# APM32M35XX register map
File version: 1.0
Registers are 32-bit, read-write, reset 0x0 unless marked. A register's access mark holds for its fields unless they carry their own. Offsets are from the block's base; [hi:lo] are bit positions; {n}, {i} and the like mark numbered series.

## SPI1 — Serial peripheral interface
Base 0x40013000
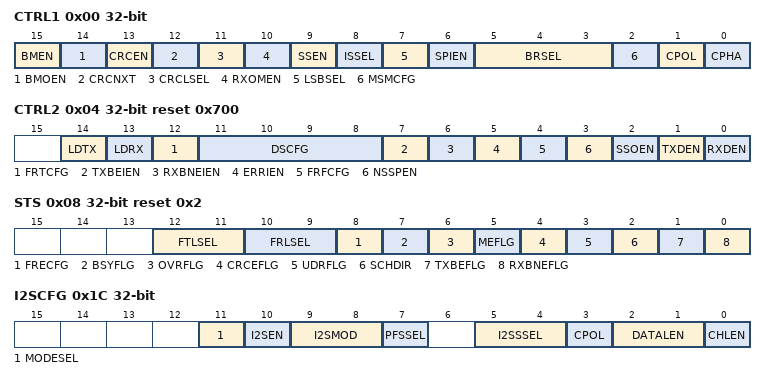
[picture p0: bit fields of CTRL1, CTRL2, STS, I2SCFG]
0x00 CTRL1 — control register 1
  [15] BMEN — Bidirectional data mode enable
  [14] BMOEN — Bidirectional Mode Output Enable
  [13] CRCEN — Hardware CRC calculation enable
  [12] CRCNXT — CRC transfer next
  [11] CRCLSEL — CRC Length Select
  [10] RXOMEN — Receive Only Mode Enable
  [9] SSEN — Software Slave Device Enable
  [8] ISSEL — Internal Slave Device Select
  [7] LSBSEL — LSB First Transfer Select
  [6] SPIEN — SPI enable
  [5:3] BRSEL — Baud Rate Divider Factor Selectl
  [2] MSMCFG — Master/Salve Mode Configure
  [1] CPOL — Clock Phase Configure
  [0] CPHA — Clock Polarity Configure
0x04 CTRL2 reset 0x700 — control register 2
  [14] LDTX — Last DMA transfer for transmission
  [13] LDRX — Last DMA transfer for reception
  [12] FRTCFG — FIFO reception threshold
  [11:8] DSCFG — Data size
  [7] TXBEIEN — Tx buffer empty interrupt enable
  [6] RXBNEIEN — RX buffer not empty interrupt enable
  [5] ERRIEN — Error interrupt enable
  [4] FRFCFG — Frame format
  [3] NSSPEN — NSS pulse management
  [2] SSOEN — SS output enable
  [1] TXDEN — Tx buffer DMA enable
  [0] RXDEN — Rx buffer DMA enable
0x08 STS access per field reset 0x2 — status register
  [12:11] FTLSEL ro — FIFO transmission level
  [10:9] FRLSEL ro — FIFO reception level
  [8] FRECFG ro — TI frame format error
  [7] BSYFLG ro — Busy flag
  [6] OVRFLG ro — Overrun flag
  [5] MEFLG ro — Mode fault
  [4] CRCEFLG rw — CRC error flag
  [3] UDRFLG ro — Underrun flag
  [2] SCHDIR ro — Channel direction
  [1] TXBEFLG ro — Transmit buffer empty
  [0] RXBNEFLG ro — Receive buffer not empty
0x0C DATA
  [15:0] DATA
0x10 CRCPOLY reset 0x7 — CRC polynomial register
  [15:0] CRCPOLY
0x14 RXCRC ro
  [15:0] RXCRC
0x18 TXCRC ro
  [15:0] TXCRC
0x1C I2SCFG — I2S configuration register
  [11] MODESEL — I2S mode selection
  [10] I2SEN — I2S enable
  [9:8] I2SMOD — I2S configuration mode
  [7] PFSSEL — PCM frame synchronization
  [5:4] I2SSSEL — I2S standard selection
  [3] CPOL — Inactive state clock polarity
  [2:1] DATALEN — Data length to be transferred
  [0] CHLEN — Channel length
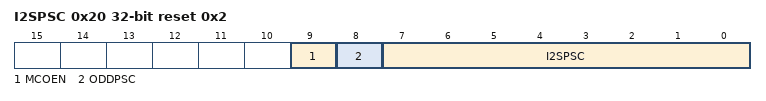
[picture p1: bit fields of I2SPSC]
0x20 I2SPSC reset 0x2 — I2S prescaler register
  [9] MCOEN — Master clock output enable
  [8] ODDPSC — Odd prescaler
  [7:0] I2SPSC — I2S prescaler

## IWDT — Independent watchdog
Base 0x40003000
0x00 KEY wo
  [15:0] KEY — Key value
0x04 PSC — Prescaler register
  [2:0] PSC — Prescaler divider
0x08 CNTRLD reset 0xFFF — Counter reload register
  [11:0] CNTRLD — Watchdog counter reload value
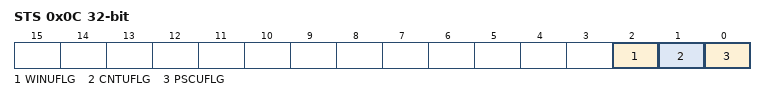
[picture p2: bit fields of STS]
0x0C STS ro — Status register
  [2] WINUFLG — Watchdog counter window value update
  [1] CNTUFLG — Watchdog counter reload value update
  [0] PSCUFLG — Watchdog prescaler value update
0x10 WIN reset 0xFFF — Window register
  [11:0] WIN — Watchdog counter window value

## WWDT — Window watchdog
Base 0x40002C00
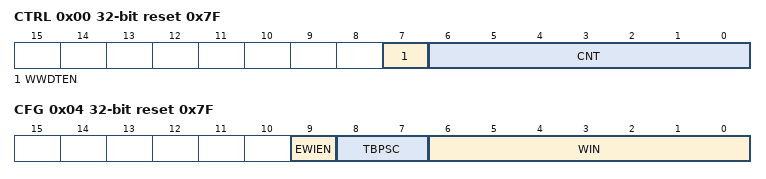
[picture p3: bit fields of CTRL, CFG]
0x00 CTRL reset 0x7F — Control register
  [7] WWDTEN — Activation bit
  [6:0] CNT — 7-bit counter
0x04 CFG reset 0x7F — Configuration register
  [9] EWIEN — Early wakeup interrupt
  [8:7] TBPSC — Timer base
  [6:0] WIN — 7-bit window value
0x08 STS — Status register
  [0] EWIFLG — Early wakeup interrupt flag

## EINT — External interrupt/event controller
Base 0x40010400
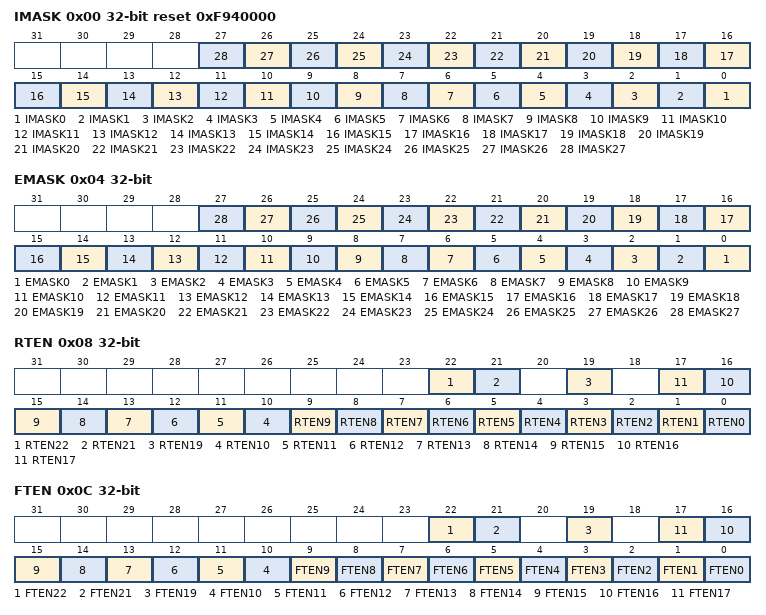
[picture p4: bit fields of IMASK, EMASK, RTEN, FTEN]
0x00 IMASK reset 0xF940000 — Interrupt mask register
  [n] IMASK{n} (n=0..27) — Interrupt Mask on line {n}
0x04 EMASK — Event mask register
  [n] EMASK{n} (n=0..27) — Event Mask on line {n}
0x08 RTEN — Rising Trigger selection register
  [22] RTEN22 — Rising trigger event configuration of line 22
  [21] RTEN21 — Rising trigger event configuration of line 21
  [19] RTEN19 — Rising trigger event configuration of line 19
  [n] RTEN{n} (n=0..17) — Rising trigger event configuration of line {n}
0x0C FTEN — Falling Trigger selection register
  [22] FTEN22 — Falling trigger event configuration of line 22
  [21] FTEN21 — Falling trigger event configuration of line 21
  [19] FTEN19 — Falling trigger event configuration of line 19
  [n] FTEN{n} (n=0..17) — Falling trigger event configuration of line {n}
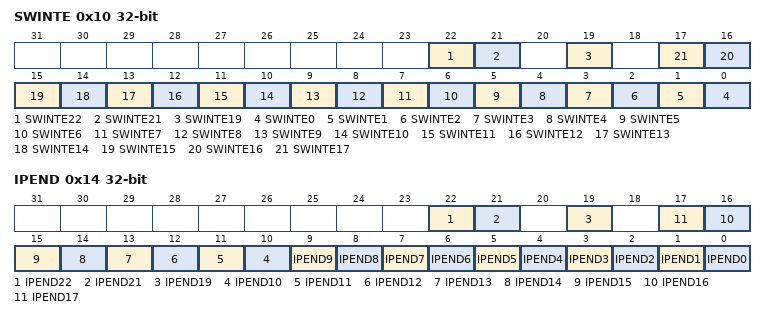
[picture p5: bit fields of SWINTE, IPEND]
0x10 SWINTE — Software interrupt event register
  [22] SWINTE22 — Software Interrupt on line22
  [21] SWINTE21 — Software Interrupt on line21
  [19] SWINTE19 — Software Interrupt on line19
  [n] SWINTE{n} (n=0..17) — Software Interrupt on line{n}
0x14 IPEND — Pending register
  [22] IPEND22 — Pending bit 22
  [21] IPEND21 — Pending bit 21
  [19] IPEND19 — Pending bit 19
  [n] IPEND{n} (n=0..17) — Pending bit {n}
